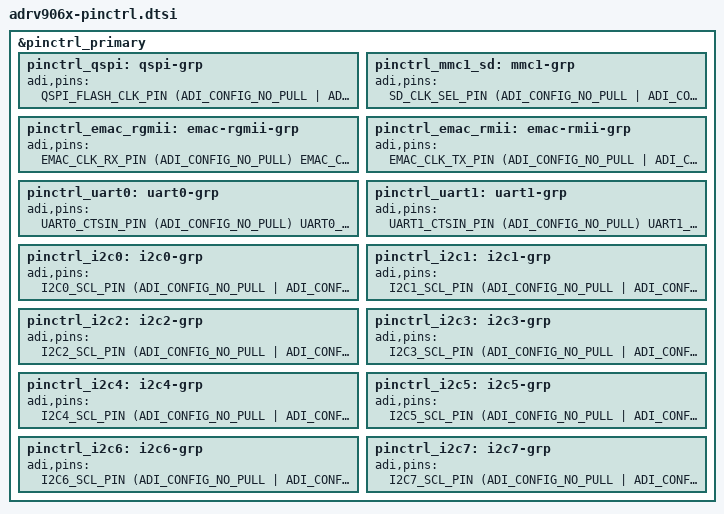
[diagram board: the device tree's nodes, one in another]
// SPDX-License-Identifier: BSD-3-Clause
/*
 * Copyright (c) 2023, Analog Devices Incorporated, All Rights Reserved
 */

#include "adrv906x_def.h"
#include "pinctrl-adi-adrv906x.h"

&pinctrl_primary {
	pinctrl_qspi: qspi-grp {
		adi,pins = <
			QSPI_FLASH_CLK_PIN	(ADI_CONFIG_NO_PULL			|	ADI_CONFIG_DRIVE_STRENGTH_4)
			QSPI_FLASH_SELB_PIN	(ADI_CONFIG_ENABLE_PULLUP		|	ADI_CONFIG_DRIVE_STRENGTH_4)
			QSPI_FLASH_D0_PIN	(ADI_CONFIG_ENABLE_SCHMITT_TRIGGER	|	ADI_CONFIG_DRIVE_STRENGTH_4)
			QSPI_FLASH_D1_PIN	(ADI_CONFIG_ENABLE_SCHMITT_TRIGGER	|	ADI_CONFIG_DRIVE_STRENGTH_4)
			QSPI_FLASH_D2_PIN	(ADI_CONFIG_ENABLE_SCHMITT_TRIGGER	|	ADI_CONFIG_DRIVE_STRENGTH_4)
			QSPI_FLASH_D3_PIN	(ADI_CONFIG_ENABLE_SCHMITT_TRIGGER	|	ADI_CONFIG_DRIVE_STRENGTH_4)
			A55_GPIO_NS_84_PIN	(ADI_CONFIG_ENABLE_PULLUP		|	ADI_CONFIG_DRIVE_STRENGTH_4)
		>;
	};

	pinctrl_mmc1_sd: mmc1-grp {
		adi,pins = <
			SD_CLK_SEL_PIN		(ADI_CONFIG_NO_PULL			|	ADI_CONFIG_DRIVE_STRENGTH_4)
			SD_CMD_PIN		(ADI_CONFIG_ENABLE_SCHMITT_TRIGGER	|	ADI_CONFIG_DRIVE_STRENGTH_4)
			SD_DATA0_PIN		(ADI_CONFIG_ENABLE_SCHMITT_TRIGGER	|	ADI_CONFIG_DRIVE_STRENGTH_4)
			SD_DATA1_PIN		(ADI_CONFIG_ENABLE_SCHMITT_TRIGGER	|	ADI_CONFIG_DRIVE_STRENGTH_4)
			SD_DATA2_PIN		(ADI_CONFIG_ENABLE_SCHMITT_TRIGGER	|	ADI_CONFIG_DRIVE_STRENGTH_4)
			SD_DATA3_PIN		(ADI_CONFIG_ENABLE_SCHMITT_TRIGGER	|	ADI_CONFIG_DRIVE_STRENGTH_4)
			SD_CARDDETECT_PIN	(ADI_CONFIG_ENABLE_SCHMITT_TRIGGER	|	ADI_CONFIG_DRIVE_STRENGTH_4)
		>;
	};

	pinctrl_emac_rgmii: emac-rgmii-grp {
		adi,pins = <
			EMAC_CLK_RX_PIN		(ADI_CONFIG_NO_PULL)
			EMAC_CLK_TX_PIN		(ADI_CONFIG_NO_PULL	|	ADI_CONFIG_DRIVE_STRENGTH_4)
			EMAC_GMII_MDC_PIN	(ADI_CONFIG_NO_PULL	|	ADI_CONFIG_DRIVE_STRENGTH_4)
			EMAC_GMII_MDIO_PIN	(ADI_CONFIG_NO_PULL	|	ADI_CONFIG_DRIVE_STRENGTH_4)
			EMAC_PHY_INTR_PIN	(ADI_CONFIG_NO_PULL)
			EMAC_PHY_RXD_0_PIN	(ADI_CONFIG_NO_PULL)
			EMAC_PHY_RXD_1_PIN	(ADI_CONFIG_NO_PULL)
			EMAC_PHY_RXD_2_PIN	(ADI_CONFIG_NO_PULL)
			EMAC_PHY_RXD_3_PIN	(ADI_CONFIG_NO_PULL)
			EMAC_PHY_RX_DV_PIN	(ADI_CONFIG_NO_PULL)
			EMAC_PHY_TXD_0_PIN	(ADI_CONFIG_NO_PULL	|	ADI_CONFIG_DRIVE_STRENGTH_4)
			EMAC_PHY_TXD_1_PIN	(ADI_CONFIG_NO_PULL	|	ADI_CONFIG_DRIVE_STRENGTH_4)
			EMAC_PHY_TXD_2_PIN	(ADI_CONFIG_NO_PULL	|	ADI_CONFIG_DRIVE_STRENGTH_4)
			EMAC_PHY_TXD_3_PIN	(ADI_CONFIG_NO_PULL	|	ADI_CONFIG_DRIVE_STRENGTH_4)
			EMAC_PHY_TXEN_PIN	(ADI_CONFIG_NO_PULL	|	ADI_CONFIG_DRIVE_STRENGTH_4)
			A55_GPIO_NS_88_PIN	(ADI_CONFIG_NO_PULL	|	ADI_CONFIG_DRIVE_STRENGTH_4)
		>;
	};

	pinctrl_emac_rmii: emac-rmii-grp {
		adi,pins = <
			EMAC_CLK_TX_PIN		(ADI_CONFIG_NO_PULL	|	ADI_CONFIG_DRIVE_STRENGTH_4)
			EMAC_GMII_MDC_PIN	(ADI_CONFIG_NO_PULL	|	ADI_CONFIG_DRIVE_STRENGTH_4)
			EMAC_GMII_MDIO_PIN	(ADI_CONFIG_NO_PULL	|	ADI_CONFIG_DRIVE_STRENGTH_4)
			EMAC_PHY_INTR_PIN	(ADI_CONFIG_NO_PULL)
			EMAC_PHY_RXD_0_PIN	(ADI_CONFIG_NO_PULL)
			EMAC_PHY_RXD_1_PIN	(ADI_CONFIG_NO_PULL)
			EMAC_PHY_RX_DV_PIN	(ADI_CONFIG_NO_PULL)
			EMAC_PHY_TXD_0_PIN	(ADI_CONFIG_NO_PULL	|	ADI_CONFIG_DRIVE_STRENGTH_4)
			EMAC_PHY_TXD_1_PIN	(ADI_CONFIG_NO_PULL	|	ADI_CONFIG_DRIVE_STRENGTH_4)
			EMAC_PHY_TXEN_PIN	(ADI_CONFIG_NO_PULL	|	ADI_CONFIG_DRIVE_STRENGTH_4)
			A55_GPIO_NS_88_PIN	(ADI_CONFIG_NO_PULL	|	ADI_CONFIG_DRIVE_STRENGTH_4)
		>;
	};

	pinctrl_uart0: uart0-grp {
		adi,pins = <
			UART0_CTSIN_PIN		(ADI_CONFIG_NO_PULL)
			UART0_RTSOUT_PIN	(ADI_CONFIG_NO_PULL	|	ADI_CONFIG_DRIVE_STRENGTH_4)
			UART0_RXSIN_PIN		(ADI_CONFIG_NO_PULL)
			UART0_TXSOUT_PIN	(ADI_CONFIG_NO_PULL	|	ADI_CONFIG_DRIVE_STRENGTH_4)
		>;
	};

	pinctrl_uart1: uart1-grp {
		adi,pins = <
			UART1_CTSIN_PIN		(ADI_CONFIG_NO_PULL)
			UART1_RTSOUT_PIN	(ADI_CONFIG_NO_PULL	|	ADI_CONFIG_DRIVE_STRENGTH_4)
			UART1_RXSIN_PIN		(ADI_CONFIG_NO_PULL)
			UART1_TXSOUT_PIN	(ADI_CONFIG_NO_PULL	|	ADI_CONFIG_DRIVE_STRENGTH_4)
		>;
	};

	pinctrl_i2c0: i2c0-grp {
		adi,pins = <
		I2C0_SCL_PIN	(ADI_CONFIG_NO_PULL  | ADI_CONFIG_DRIVE_STRENGTH_4)	/* DedicatedIO */
		I2C0_SDA_PIN	(ADI_CONFIG_NO_PULL  | ADI_CONFIG_DRIVE_STRENGTH_4)	/* DedicatedIO */
		>;
	};

	pinctrl_i2c1: i2c1-grp {
		adi,pins = <
		I2C1_SCL_PIN	(ADI_CONFIG_NO_PULL  | ADI_CONFIG_DRIVE_STRENGTH_4)
		I2C1_SDA_PIN	(ADI_CONFIG_NO_PULL  | ADI_CONFIG_DRIVE_STRENGTH_4)
		>;
	};

	pinctrl_i2c2: i2c2-grp {
		adi,pins = <
		I2C2_SCL_PIN	(ADI_CONFIG_NO_PULL  | ADI_CONFIG_DRIVE_STRENGTH_4)
		I2C2_SDA_PIN	(ADI_CONFIG_NO_PULL  | ADI_CONFIG_DRIVE_STRENGTH_4)
		>;
	};

	pinctrl_i2c3: i2c3-grp {
		adi,pins = <
		I2C3_SCL_PIN	(ADI_CONFIG_NO_PULL  | ADI_CONFIG_DRIVE_STRENGTH_4)
		I2C3_SDA_PIN	(ADI_CONFIG_NO_PULL  | ADI_CONFIG_DRIVE_STRENGTH_4)
		>;
	};

	pinctrl_i2c4: i2c4-grp {
		adi,pins = <
		I2C4_SCL_PIN	(ADI_CONFIG_NO_PULL  | ADI_CONFIG_DRIVE_STRENGTH_4)
		I2C4_SDA_PIN	(ADI_CONFIG_NO_PULL  | ADI_CONFIG_DRIVE_STRENGTH_4)
		>;
	};

	pinctrl_i2c5: i2c5-grp {
		adi,pins = <
		I2C5_SCL_PIN	(ADI_CONFIG_NO_PULL  | ADI_CONFIG_DRIVE_STRENGTH_4)
		I2C5_SDA_PIN	(ADI_CONFIG_NO_PULL  | ADI_CONFIG_DRIVE_STRENGTH_4)
		>;
	};

	pinctrl_i2c6: i2c6-grp {
		adi,pins = <
		I2C6_SCL_PIN	(ADI_CONFIG_NO_PULL  | ADI_CONFIG_DRIVE_STRENGTH_4)
		I2C6_SDA_PIN	(ADI_CONFIG_NO_PULL  | ADI_CONFIG_DRIVE_STRENGTH_4)
		>;
	};

	pinctrl_i2c7: i2c7-grp {
		adi,pins = <
		I2C7_SCL_PIN	(ADI_CONFIG_NO_PULL  | ADI_CONFIG_DRIVE_STRENGTH_4)
		I2C7_SDA_PIN	(ADI_CONFIG_NO_PULL  | ADI_CONFIG_DRIVE_STRENGTH_4)
		>;
	};

};
